# TC37XPD register map
Vendor: Infineon; Series: ATVMC; File version: 100
CPU: other r0p0, little endian, MPU, FPU, vendor SysTick, 4 interrupt priority bits
Registers are 32-bit, read-write, reset 0x0 unless marked. A register's access mark holds for its fields unless they carry their own. Offsets are from the block's base; [hi:lo] are bit positions; lines under a group give offsets from that group; {n}, {i} and the like mark numbered series.

## PSI5 (part 2 of 2)
Base 0xF0005000
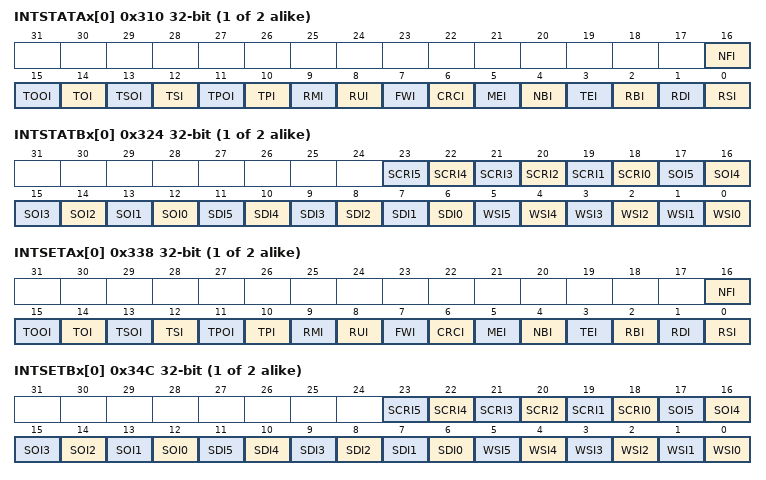
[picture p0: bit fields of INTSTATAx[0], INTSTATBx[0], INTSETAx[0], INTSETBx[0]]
{0x310+4i} INTSTATAx[{i}] (i=0..1) ro — Interrupt Status Register A 0 resetvalue={Application Reset:0x0}
  [16] NFI — No Frame Received Interrupt Flag NFI. This bit is set at the end of a slot if a frame is expected in the slot and SOF was not received in the slot. A special case is where an SOF is received in slot 0. In this scenario the NFI bit is only set at the end of slot 1 if a frame is expected in slot 1 and an EOF was not received in slot 1. If only the two start bits are received and no further data this x201c SOF x201d is discarded completely and treated like no frame received as well. If the x201c SOF only frame x201d crosses the WDL NFI occurs after WDL and EOF detection. If RCRBx.VBS is set an empty frame is stored anyhow. In this case RDIx is issued as well. The only valid information is SC TS captured at the end of the slot and this bit NFI . This bit can be cleared by bit INTCLRAx.NFI. This bit can be set by bit INTSETAx.NFI. This bit is set independently from INTENAx.
  [15] TOOI — Transmit Shift Overflow Interrupt Request Flag TOOI. This bit is set after if SORL H is written while TOF is set. The old data is NOT overwritten. This bit can be cleared by bit INTCLRAx.TOOI. This bit can be set by bit INTSETAx.TOOI. This bit is set independently from INTENAx.
  [14] TOI — Transfer Output Interrupt Request Flag TOI. This bit is set after last bit to be transferred has been moved from SORL H to the pulse generator. Thus a new value can be written to SORL Hx. This bit is NOT cleared by writing SORL Hx. This bit can be cleared by bit INTCLRAx.TOI. This bit can be set by bit INTSETAx.TOI. This bit is set independently from INTENAx.
  [13] TSOI — Transmit Shift Overflow Interrupt Request Flag TSOI. This bit is set after if SSRL H is written while TSF is set. The old data is NOT overwritten. This bit can be cleared by bit INTCLRAx.TSOI. This bit can be set by bit INTSETAx.TSOI. This bit is set independently from INTENAx.
  [12] TSI — Transfer Shift Interrupt Request Flag TSI. This bit is set after data to be transferred has been moved from SSRL H to SORL H. Thus a new value can be written to SSRL Hx. This bit is NOT cleared by writing SSRL Hx. This bit can be cleared by bit INTCLRAx.TSI. This bit can be set by bit INTSETAx.TSI. This bit is set independently from INTENAx.
  [11] TPOI — Transmit Preparation Overflow Interrupt Request Flag TPOI. This bit is set after if SDRL H is written while TPF is set. The old data is NOT overwritten. This bit can be cleared by bit INTCLRAx.TPOI. This bit can be set by bit INTSETAx.TPOI. This bit is set independently from INTENAx.
  [10] TPI — Transfer Preparation Interrupt Request Flag TPI. This bit is set after data to be transferred has been moved from SDRL H to SSRL H. Thus a new value can be written to SDRL Hx and the prepared data can be checked and modified by SW. This bit is automatically cleared by writing SDRx. This is an exception It allows for DMA transfers without CPU activity. This bit can be cleared by bit INTCLRAx.TDI. This bit can be set by bit INTSETAx.TDI. This bit is set independently from INTENAx.
  [9] RMI — Receive Memory Overflow Flag RMI. This bit is set after a frame has been received while RDIOVx.RDI RFCx.WRP is set. I.e. the kernel wants to set flag RDIxWRP and finds this flag already set. The old data is overwritten by the new data in the buffer memory. This bit can be cleared by bit INTCLRAx.RMIx. This bit can be set by bit INTSETAx.RMIx. This bit is set independently from INTENAx.
  [8] RUI — Receive Memory Underrun Interrupt Request Flag RUI. This bit is set after a SPB master reads from FIFO while no new data was available. See RFCx This bit can be cleared by bit INTCLRAx.RUI. This bit can be set by bit INTSETAx.RUI. This bit is set independently from INTENAx.
  [7] FWI — FIFO Warning Level Request Flag FWI. This bit is set after if the configured warning level of the FIFOx was reached. See RFCx This bit can be cleared by bit INTCLRAx.FWI. This bit can be set by bit INTSETAx.FWI. This bit is set independently from INTENAx.
  [6] CRCI — CRC Error Request Flag CRCI. This bit is set if the CRC fails. Set as well if CRC can not be calculated PDL 0 CRC cut off by Manchester Error too few bits BOT Sync Pulse This bit can be cleared by bit INTCLRAx.CRCI. This bit can be set by bit INTSETAx.CRCI. This bit is set independently from INTENAx.
  [5] MEI — Error in Message Bits Flag MEI. This bit is set if a manchester error occurred in Bit M0 or M1. Only if configured in RCRBx.MSG Note that the frame after the error might be completely wrong. The frame is no longer checked from the Manchester error on zeros are inserted and a start of frame is looked for no occurrence of edges for at least one bit time followed by two zero bits. This bit can be cleared by bit INTCLRAx.MEI. This bit can be set by bit INTSETAx.MEI. This bit is set independently from INTENAx.
  [4] NBI — Number of Bits Wrong Request Flag NBI. This bit is set if the last frame received less bits than expected but no Manchester coding error occurred until S1 S2 M0 and M1 where received. I. e. fewer bits or Manchester error after M1 received. Note that the frame after the error might be completely wrong. The frame is no longer checked from the Manchester error on zeros are inserted and a start of frame is looked for no occurrence of edges for at least one bit time followed by two zero bits. This bit can be cleared by bit INTCLRAx.NBI. This bit can be set by bit INTSETAx.NBI. This bit is set independently from INTENAx.
  [3] TEI — Time Slot Error Interrupt Request Flag TEI. In Synchronous Mode RCRAx.ASYN 0 this bit is set if the SOF and the EOF of a frame are received in different time slots. The slots are constraint by the watch dog timer see WDTxy . In Asynchronous Mode RCRAx.ASYN 1 this bit is set if the distance between two frames is longer than specified in WDL0. This bit can be cleared by bit INTCLRAx.TEI. This bit can be set by bit INTSETAx.TEI. This bit is set independently from INTENAx.
  [2] RBI — Receive Buffer Overflow Interrupt Request Flag RBI. This bit is set after a frame has been received while the old one was not read from RDRHx. I.e. the kernel wants to set any of the two interrupts RSI and RDI and finds any of these two interrupts already set. The old data is overwritten by the new data. Thus RBI can be ignored if the receive memory is used. This bit is NOT cleared by reading RDRx. This bit can be cleared by bit INTCLRAx.RBI. This bit can be set by bit INTSETAx.RBI. This bit is set independently from INTENAx.
  [1] RDI — Receive Data Interrupt Request Flag RDI. RDI is activated when a received frame is moved to a Receive Data Register RDRL Hx. Both RDI and RSI will be issued together at correct reception. This bit can be cleared by bit INTCLRAx.RDI. This bit can be set by bit INTSETAx.RDI. This bit is set independently from INTENAx.
  [0] RSI — Receive Success Interrupt Request Flag RSI. This bit is set at the successfully received end of a frame. It indicates that this frame is free of the errors NFI TEI NBI MEI CRCI if selected to be taken into account in register GCR. This bit can be cleared by bit INTCLRAx.RSI. This bit can be set by bit INTSETAx.RSI. This bit is set independently from INTENAx.
{0x324+4i} INTSTATBx[{i}] (i=0..1) ro — Interrupt Status Register B 0 resetvalue={Application Reset:0x0}
  [n+18] SCRI{n} (n=0..5) — Serial Data CRC Error Request Flag SCRI5. This bit is set if the CRC of the serial message fails. This includes a check of the Messaging bit field for correct 0 values of bit 1 in frames 7 13 and 18. This bit can be cleared by bit INTCLRBx.SCRIy. This bit can be set by bit INTSETx.SCRIy. This bit is set independently from INTENBx.
  [n+12] SOI{n} (n=0..5) — Serial Data Buffer Overrun Interrupt Request Flag SOI5. This bit is set if the HW wants to set SDIy while SDIy is still set. This bit can be cleared by bit INTCLRBx.SOIy. This bit can be set by bit INTSETBx.SOIy. This bit is set independently from INTENBx.
  [n+6] SDI{n} (n=0..5) — Serial Data Receive Interrupt Request Flag SDI5. This bit is set after all serial data bits have been received via the Messaging bit field of slot y. This does NOT indicates a successful check of the CRC. This bit can be cleared by bit INTCLRBx.SDIy. This bit can be set by bit INTSETBx.SDIy. This bit is set independently from INTENBx.
  [n] WSI{n} (n=0..5) — Wrong Serial Protocol Error Request Flag WSI5. This bit is set if the Messaging bits are configured and do not show a start sequence for more than 18 frames of slot y. This bit can be cleared by bit INTCLRBx.WSIy. This bit can be set by bit INTSETBx.WSIy. This bit is set independently from INTENBx.
{0x338+4i} INTSETAx[{i}] (i=0..1) wo — Interrupt Set Register A 0 resetvalue={Application Reset:0x0}
  [16] NFI — Set Interrupt Request Flag NFI NFI. Setting this bit set bit INTSTATx.NFI. Clearing this bit has no effect. Reading this bit returns always zero.
  [15] TOOI — Set Interrupt Request Flag TOOI TOOI. Setting this bit set bit INTSTATx.TOOI. Clearing this bit has no effect. Reading this bit returns always zero.
  [14] TOI — Set Interrupt Request Flag TOI TOI. Setting this bit set bit INTSTATx.TOI. Clearing this bit has no effect. Reading this bit returns always zero.
  [13] TSOI — Set Interrupt Request Flag TSOI TSOI. Setting this bit set bit INTSTATx.TSOI. Clearing this bit has no effect. Reading this bit returns always zero.
  [12] TSI — Set Interrupt Request Flag TSI TSI. Setting this bit set bit INTSTATx.TSI. Clearing this bit has no effect. Reading this bit returns always zero.
  [11] TPOI — Set Interrupt Request Flag TPOI TPOI. Setting this bit set bit INTSTATx.TPOI. Clearing this bit has no effect. Reading this bit returns always zero.
  [10] TPI — Set Interrupt Request Flag TPI TPI. Setting this bit set bit INTSTATx.TPI. Clearing this bit has no effect. Reading this bit returns always zero.
  [9] RMI — Set Interrupt Request Flag RMI RMI. Setting this bit set bit INTSTATx.RMI. Clearing this bit has no effect. Reading this bit returns always zero.
  [8] RUI — Set Interrupt Request Flag RUI RUI. Setting this bit set bit INTSTATx.RUI. Clearing this bit has no effect. Reading this bit returns always zero.
  [7] FWI — Set Interrupt Request Flag FWI FWI. Setting this bit set bit INTSTATx.FWI. Clearing this bit has no effect. Reading this bit returns always zero.
  [6] CRCI — Set Interrupt Request Flag CRCI CRCI. Setting this bit set bit INTSTATx.CRCI. Clearing this bit has no effect. Reading this bit returns always zero.
  [5] MEI — Set Interrupt Request Flag MEI MEI. Setting this bit set bit INTSTATx.MEI. Clearing this bit has no effect. Reading this bit returns always zero.
  [4] NBI — Set Interrupt Request Flag NBI NBI. Setting this bit set bit INTSTATx.NBI. Clearing this bit has no effect. Reading this bit returns always zero.
  [3] TEI — Set Interrupt Request Flag TEI TEI. Setting this bit set bit INTSTATx.TEI. Clearing this bit has no effect. Reading this bit returns always zero.
  [2] RBI — Set Interrupt Request Flag RBI RBI. Setting this bit set bit INTSTATx.RBI. Clearing this bit has no effect. Reading this bit returns always zero.
  [1] RDI — Set Interrupt Request Flag RDI RDI. Setting this bit set bit INTSTATx.RDI. Clearing this bit has no effect. Reading this bit returns always zero.
  [0] RSI — Set Interrupt Request Flag RSI RSI. Setting this bit set bit INTSTATx.RSI. Clearing this bit has no effect. Reading this bit returns always zero.
{0x34C+4i} INTSETBx[{i}] (i=0..1) wo — Interrupt Set Register B 0 resetvalue={Application Reset:0x0}
  [n+18] SCRI{n} (n=0..5) — Set Interrupt Request Flag SCRI5 SCRI5. Setting this bit set bit INTSTATx.SCRIy. Clearing this bit has no effect. Reading this bit returns always zero.
  [n+12] SOI{n} (n=0..5) — Set Interrupt Request Flag SOI5 SOI5. Setting this bit set bit INTSTATx.SOIy. Clearing this bit has no effect. Reading this bit returns always zero.
  [n+6] SDI{n} (n=0..5) — Set Interrupt Request Flag SDI5 SDI5. Setting this bit set bit INTSTATx.SDIy. Clearing this bit has no effect. Reading this bit returns always zero.
  [n] WSI{n} (n=0..5) — Set Interrupt Request Flag WSI5 WSI5. Setting this bit set bit INTSTATx.WSIy. Clearing this bit has no effect. Reading this bit returns always zero.
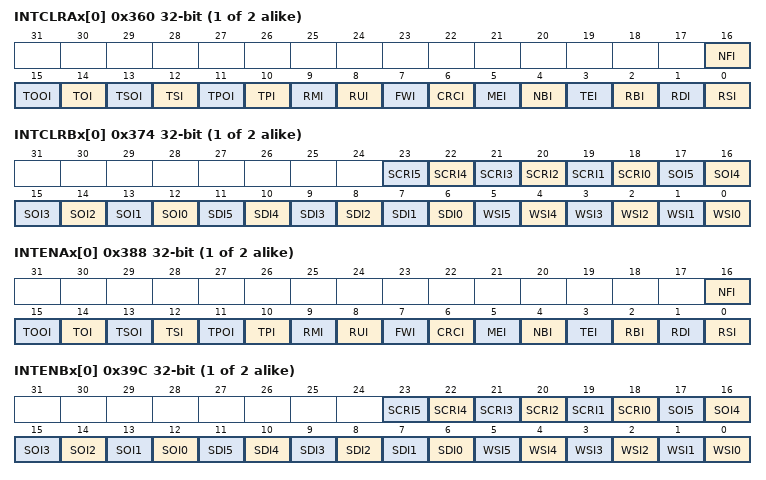
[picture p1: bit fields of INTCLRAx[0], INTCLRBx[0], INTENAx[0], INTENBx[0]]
{0x360+4i} INTCLRAx[{i}] (i=0..1) wo — Interrupt Clear Register A 0 resetvalue={Application Reset:0x0}
  [16] NFI — Clear Interrupt Request Flag NFI NFI. Setting this bit clears bit INTSTATx.NFI. Clearing this bit has no effect. Reading this bit returns always zero.
  [15] TOOI — Clear Interrupt Request Flag TOOI TOOI. Setting this bit clears bit INTSTATx.TOOI. Clearing this bit has no effect. Reading this bit returns always zero.
  [14] TOI — Clear Interrupt Request Flag TOI TOI. Setting this bit clears bit INTSTATx.TOI. Clearing this bit has no effect. Reading this bit returns always zero.
  [13] TSOI — Clear Interrupt Request Flag TSOI TSOI. Setting this bit clears bit INTSTATx.TSOI. Clearing this bit has no effect. Reading this bit returns always zero.
  [12] TSI — Clear Interrupt Request Flag TSI TSI. Setting this bit clears bit INTSTATx.TSI. Clearing this bit has no effect. Reading this bit returns always zero.
  [11] TPOI — Clear Interrupt Request Flag TPOI TPOI. Setting this bit clears bit INTSTATx.TPOI. Clearing this bit has no effect. Reading this bit returns always zero.
  [10] TPI — Clear Interrupt Request Flag TPI TPI. Setting this bit clears bit INTSTATx.TPI. Clearing this bit has no effect. Reading this bit returns always zero.
  [9] RMI — Clear Interrupt Request Flag RMI RMI. Setting this bit clears bit INTSTATx.RMI. Clearing this bit has no effect. Reading this bit returns always zero.
  [8] RUI — Clear Interrupt Request Flag RUI RUI. Setting this bit clears bit INTSTATx.RUI. Clearing this bit has no effect. Reading this bit returns always zero.
  [7] FWI — Clear Interrupt Request Flag FWI FWI. Setting this bit clears bit INTSTATx.FWI. Clearing this bit has no effect. Reading this bit returns always zero.
  [6] CRCI — Clear Interrupt Request Flag CRCI CRCI. Setting this bit clears bit INTSTATx.CRCI. Clearing this bit has no effect. Reading this bit returns always zero.
  [5] MEI — Clear Interrupt Request Flag MEI MEI. Setting this bit clears bit INTSTATx.MEI. Clearing this bit has no effect. Reading this bit returns always zero.
  [4] NBI — Clear Interrupt Request Flag NBI NBI. Setting this bit clears bit INTSTATx.NBI. Clearing this bit has no effect. Reading this bit returns always zero.
  [3] TEI — Clear Interrupt Request Flag TEI TEI. Setting this bit clears bit INTSTATx.TEI. Clearing this bit has no effect. Reading this bit returns always zero.
  [2] RBI — Clear Interrupt Request Flag RBI RBI. Setting this bit clears bit INTSTATx.RBI. Clearing this bit has no effect. Reading this bit returns always zero.
  [1] RDI — Clear Interrupt Request Flag RDI RDI. Setting this bit clears bit INTSTATx.RDI. Clearing this bit has no effect. Reading this bit returns always zero.
  [0] RSI — Clear Interrupt Request Flag RSI RSI. Setting this bit clears bit INTSTATx.RSI. Clearing this bit has no effect. Reading this bit returns always zero.
{0x374+4i} INTCLRBx[{i}] (i=0..1) wo — Interrupt Clear Register A 0 resetvalue={Application Reset:0x0}
  [n+18] SCRI{n} (n=0..5) — Clear Interrupt Request Flag SCRI5 SCRI5. Setting this bit clears bit INTSTATx.SCRIy. Clearing this bit has no effect. Reading this bit returns always zero.
  [n+12] SOI{n} (n=0..5) — Clear Interrupt Request Flag SOI5 SOI5. Setting this bit clears bit INTSTATx.SOIy. Clearing this bit has no effect. Reading this bit returns always zero.
  [n+6] SDI{n} (n=0..5) — Clear Interrupt Request Flag SDI5 SDI5. Setting this bit clears bit INTSTATx.SDIy. Clearing this bit has no effect. Reading this bit returns always zero.
  [n] WSI{n} (n=0..5) — Clear Interrupt Request Flag WSI5 WSI5. Setting this bit clears bit INTSTATx.WSIy. Clearing this bit has no effect. Reading this bit returns always zero.
{0x388+4i} INTENAx[{i}] (i=0..1) — Interrupt Enable Register A 0 resetvalue={Application Reset:0x0}
  [16] NFI — Enable Interrupt Request NFI NFI
  [15] TOOI — Enable Interrupt Request TOOI TOOI
  [14] TOI — Enable Interrupt Request TOI TOI
  [13] TSOI — Enable Interrupt Request TSOI TSOI
  [12] TSI — Enable Interrupt Request TSI TSI
  [11] TPOI — Enable Interrupt Request TPOI TPOI
  [10] TPI — Enable Interrupt Request TPI TPI
  [9] RMI — Enable Interrupt Request RMII RMI
  [8] RUI — Enable Interrupt Request RUI RUI
  [7] FWI — Enable Interrupt Request FWI FWI
  [6] CRCI — Enable Interrupt Request CRCI CRCI
  [5] MEI — Enable Interrupt Request MEII MEI
  [4] NBI — Enable Interrupt Request NBI NBI
  [3] TEI — Enable Interrupt Request TEI TEI
  [2] RBI — Enable Interrupt Request RBI RBI
  [1] RDI — Enable Interrupt Request RDI RDI
  [0] RSI — Enable Interrupt Request RSI RSI
{0x39C+4i} INTENBx[{i}] (i=0..1) — Interrupt Enable Register B 0 resetvalue={Application Reset:0x0}
  [n+18] SCRI{n} (n=0..5) — Enable Interrupt Request SCRI5 SCRI5
  [n+12] SOI{n} (n=0..5) — Enable Interrupt Request SOI5 SOI5
  [n+6] SDI{n} (n=0..5) — Enable Interrupt Request SDI5 SDI5
  [n] WSI{n} (n=0..5) — Enable Interrupt Request WSI5 WSI5
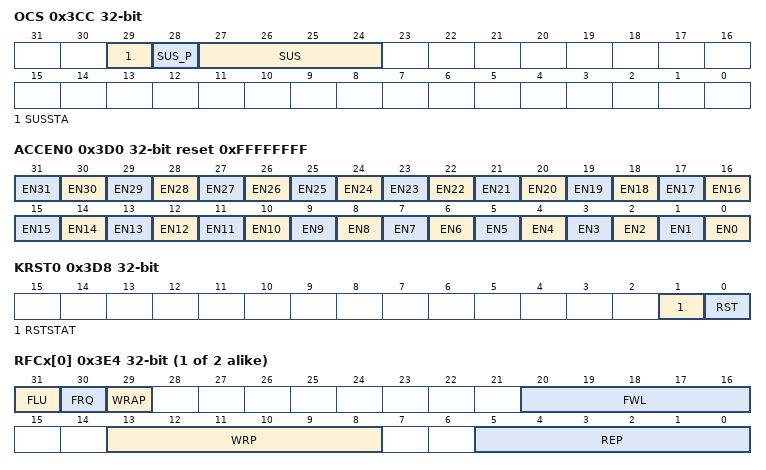
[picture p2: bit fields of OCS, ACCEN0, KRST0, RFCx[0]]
0x3CC OCS access per field — OCDS Control and Status resetvalue={Debug Reset:0x0}
  [29] SUSSTA ro — Suspend State SUSSTA
  [28] SUS_P wo — SUS Write Protection SUS P. SUS is only written when SUS P is 1 otherwise unchanged. Read as 0.
  [27:24] SUS rw — OCDS Suspend Control SUS. Controls the sensitivity to the suspend signal coming from the OCDS Trigger Switch OTGS
0x3D0 ACCEN0 reset 0xFFFFFFFF — Access Enable Register 0 resetvalue={Application Reset:0x0FFFFFFFF}
  [n] EN{n} (n=0..31) — Access Enable for Master TAG ID 31 EN31. This bit enables write access to the module kernel addresses for transactions with the Master TAG ID n
0x3D8 KRST0 access per field — Kernel Reset Register 0 resetvalue={Application Reset:0x0}
  [1] RSTSTAT ro — Kernel Reset Status RSTSTAT. This bit indicates wether a kernel reset was executed or not. This bit is set by the BPI FPI after the execution of a kernel reset in the same clock cycle both reset bits. This bit can be cleared by writing with 1 to the CLR bit in the related KRSTCLR register.
  [0] RST rw — Kernel Reset RST. This reset bit can be used to request for a kernel reset. The kernel reset will be executed if the reset bits of both kernel registers are set. The RST bit will be cleared re set to 0 by the BPI FPI after the kernel reset was executed.
0x3DC KRST1 — Kernel Reset Register 1 resetvalue={Application Reset:0x0}
  [0] RST — Kernel Reset RST. This reset bit can be used to request for a kernel reset. The kernel reset will be executed if the reset bits of both kernel reset registers is set. The RST bit will be cleared re set to 0 by the BPI FPI after the kernel reset was executed.
0x3E0 KRSTCLR wo — Kernel Reset Status Clear Register resetvalue={Application Reset:0x0}
  [0] CLR — Kernel Reset Status Clear CLR. Read always as 0.
{0x3E4+4i} RFCx[{i}] (i=0..1) access per field — Receive FIFO Control Register 0 resetvalue={Application Reset:0x0}
  [31] FLU wo — Flush FLU. if set FIFO read and write pointers are cleared. Bits and WRAP are cleared. SW needs to clear interrupts as needed. This bit can only be set and is cleared by HW. Always read as 0.
  [30] FRQ ro — Flush Request FRQ. if set FIFO read and write pointers are not incremented any more due to excessive RMI. Too many overrun conditions . This bit is cleared when FLU is set.
  [29] WRAP ro — Write Pointer WRAP Indicator WRAP. If set the Write Pointer is one wrap around ahead of the Read Pointer. It is cleared if the Read Pointer wraps around too or when FLU is set by SW.
  [20:16] FWL rw — FIFO Warning Level FWL. Number of new entries at which the FIFO Warning Interrupt FWIx is set automatically. For calculation WRP and REP are used. I.e. only if the memory is read via RDFx this works properly.
  [13:8] WRP ro — FIFO Ring Buffer Write Pointer WRP. points to the buffer written last. Incremented before write. The last bit indicates if RDMxH or RDMxL is written. This LSB is ignored for FWL comparison WRP REP collision RBI RUI .
  [5:0] REP ro — FIFO Read Pointer REP. points to the buffer to be read next. Incremented after read. The last bit bit indicates if RDMxH or RDMxL is read. This LSB is ignored for FWL comparison WRP REP collision RBI RUI
{0x3F8+4i} RDFx[{i}] (i=0..1) ro — Receive Data FIFO 0 resetvalue={Application Reset:0x0}
  [31:0] RD — RD RD. Shows the content of RDML Hxy y RFCx.REP 5 1 L H RFCx.REP 0 . Reading this register triggers incrementation of REP and presentation of next FIFO value at next read access Once a complete buffer is read 64 bit 2 accesses to RDF all overview flags for this very buffer are cleared automatically.
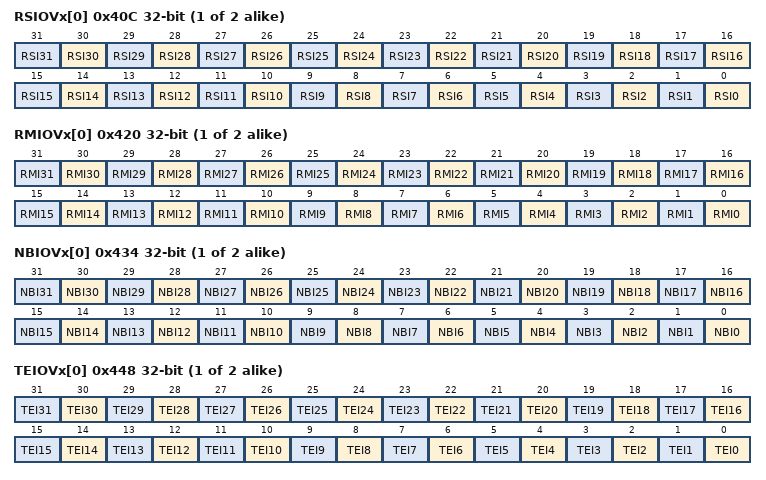
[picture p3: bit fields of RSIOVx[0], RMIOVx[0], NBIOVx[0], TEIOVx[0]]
{0x40C+4i} RSIOVx[{i}] (i=0..1) ro — RSI Overview Register 0 resetvalue={Application Reset:0x0}
  [n] RSI{n} (n=0..31) — RSI Flag of Buffer 31 RSI31. Copied from INTSTATAx at frame end while RFCx.WRP pointed to buffer y. This bit can be cleared by bit RSICLRx.RSIy. This bit can be set by bit RSISETx.RSIy.
{0x420+4i} RMIOVx[{i}] (i=0..1) ro — RMI Overview Register 0 resetvalue={Application Reset:0x0}
  [n] RMI{n} (n=0..31) — RMI Flag of Buffer 31 RMI31. Copied from INTSTATAx at frame end while RFCx.WRP pointed to buffer y. This bit can be cleared by bit RMICLRx.RMIy. This bit can be set by bit RMISETx.RMIy.
{0x434+4i} NBIOVx[{i}] (i=0..1) ro — NBI Overview Register 0 resetvalue={Application Reset:0x0}
  [n] NBI{n} (n=0..31) — NBI Flag of Buffer 31 NBI31. Copied from INTSTATAx at frame end while RFCx.WRP pointed to buffer y. This bit can be cleared by bit NBICLRx.NBIy. This bit can be set by bit NBISETx.NBIy.
{0x448+4i} TEIOVx[{i}] (i=0..1) ro — TEI Overview Register 0 resetvalue={Application Reset:0x0}
  [n] TEI{n} (n=0..31) — TEI Flag of Buffer 31 TEI31. Copied from INTSTATAx at frame end while RFCx.WRP pointed to buffer y. This bit can be cleared by bit TEICLRx.TEIy. This bit can be set by bit TEISETx.TEIy.
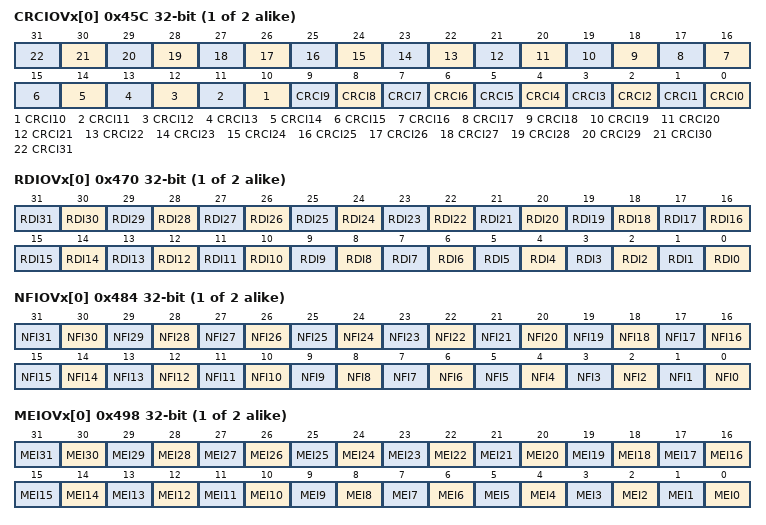
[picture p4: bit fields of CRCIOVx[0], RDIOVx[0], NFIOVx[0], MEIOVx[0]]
{0x45C+4i} CRCIOVx[{i}] (i=0..1) ro — CRCI Overview Register 0 resetvalue={Application Reset:0x0}
  [n] CRCI{n} (n=0..31) — CRCI Flag of Buffer 31 CRCI31. Copied from INTSTATAx at frame end while RFCx.WRP pointed to buffer y. This bit can be cleared by bit CRCICLRx.CRCIy. This bit can be set by bit CRCISETx.CRCIy.
{0x470+4i} RDIOVx[{i}] (i=0..1) ro — RDI Overview Register 0 resetvalue={Application Reset:0x0}
  [n] RDI{n} (n=0..31) — RDI Flag of Buffer 31 RDI31. Copied from INTSTATAx at frame end while RFCx.WRP pointed to buffer y. This bit can be cleared by bit RDICLRx.RDIy. This bit can be set by bit RDISETx.RDIy.
{0x484+4i} NFIOVx[{i}] (i=0..1) ro — NFI Overview Register 0 resetvalue={Application Reset:0x0}
  [n] NFI{n} (n=0..31) — NFI Flag of Buffer 31 NFI31. Copied from INTSTATAx at frame end while RFCx.WRP pointed to buffer y. This bit can be cleared by bit NFICLRx.NFIy. This bit can be set by bit NFISETx.NFIy.
{0x498+4i} MEIOVx[{i}] (i=0..1) ro — MEI Overview Register 0 resetvalue={Application Reset:0x0}
  [n] MEI{n} (n=0..31) — MEI Flag of Buffer 31 MEI31. Copied from INTSTATAx at frame end while RFCx.WRP pointed to buffer y. This bit can be cleared by bit MEICLRx.MEIy. This bit can be set by bit MEISETx.MEIy.
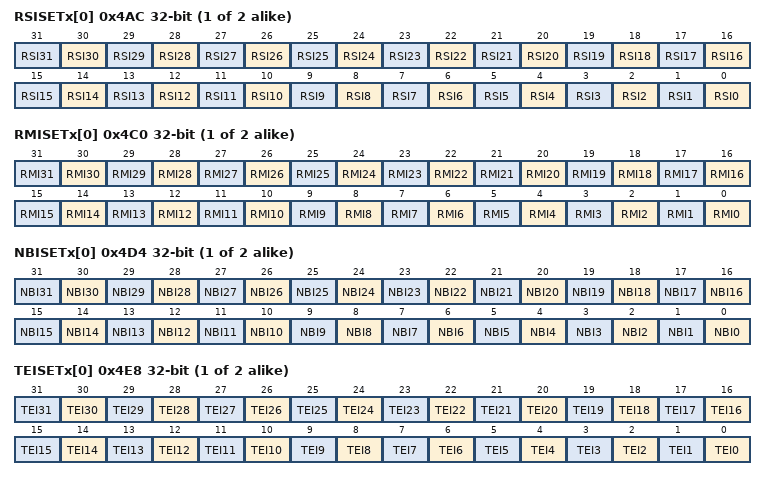
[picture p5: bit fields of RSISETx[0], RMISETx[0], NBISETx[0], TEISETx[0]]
{0x4AC+4i} RSISETx[{i}] (i=0..1) wo — RSI Overview Set Register 0 resetvalue={Application Reset:0x0}
  [n] RSI{n} (n=0..31) — Set RSI Flag of Buffer 31 RSI31. Setting this bit sets bit RSIOVx.RSIy Clearing this bit has no effect. Reading this bit returns always zero.
{0x4C0+4i} RMISETx[{i}] (i=0..1) wo — RMI Overview Set Register 0 resetvalue={Application Reset:0x0}
  [n] RMI{n} (n=0..31) — Set RMI Flag of Buffer 31 RMI31. Setting this bit sets bit RMIOVx.RMIy Clearing this bit has no effect. Reading this bit returns always zero.
{0x4D4+4i} NBISETx[{i}] (i=0..1) wo — NBI Overview Set Register 0 resetvalue={Application Reset:0x0}
  [n] NBI{n} (n=0..31) — Set NBI Flag of Buffer 31 NBI31. Setting this bit sets bit NBIOVx.NBIy Clearing this bit has no effect. Reading this bit returns always zero.
{0x4E8+4i} TEISETx[{i}] (i=0..1) wo — TEI Overview Set Register 0 resetvalue={Application Reset:0x0}
  [n] TEI{n} (n=0..31) — Set TEI Flag of Buffer 31 TEI31. Setting this bit sets bit TEIOVx.TEIy Clearing this bit has no effect. Reading this bit returns always zero.
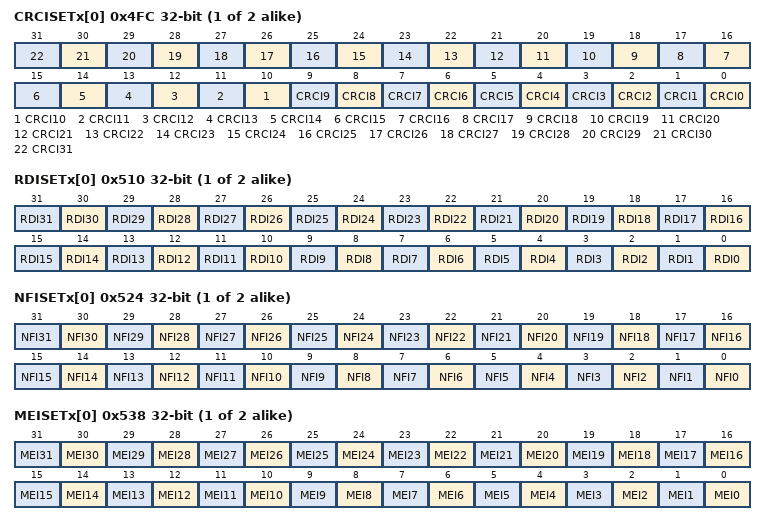
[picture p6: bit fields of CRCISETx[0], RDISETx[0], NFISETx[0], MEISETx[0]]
{0x4FC+4i} CRCISETx[{i}] (i=0..1) wo — CRCI Overview Set Register 0 resetvalue={Application Reset:0x0}
  [n] CRCI{n} (n=0..31) — Set CRCI Flag of Buffer 31 CRCI31. Setting this bit sets bit CRCIOVx.CRCIy Clearing this bit has no effect. Reading this bit returns always zero.
{0x510+4i} RDISETx[{i}] (i=0..1) wo — RDI Overview Set Register 0 resetvalue={Application Reset:0x0}
  [n] RDI{n} (n=0..31) — Set RDI Flag of Buffer 31 RDI31. Setting this bit sets bit RDIOVx.RDIy Clearing this bit has no effect. Reading this bit returns always zero.
{0x524+4i} NFISETx[{i}] (i=0..1) wo — NFI Overview Set Register 0 resetvalue={Application Reset:0x0}
  [n] NFI{n} (n=0..31) — Set NFI Flag of Buffer 31 NFI31. Setting this bit sets bit NFIOVx.NFIy Clearing this bit has no effect. Reading this bit returns always zero.
{0x538+4i} MEISETx[{i}] (i=0..1) wo — MEI Overview Set Register 0 resetvalue={Application Reset:0x0}
  [n] MEI{n} (n=0..31) — Set MEI Flag of Buffer 31 MEI31. Setting this bit sets bit MEIOVx.MEIy Clearing this bit has no effect. Reading this bit returns always zero.
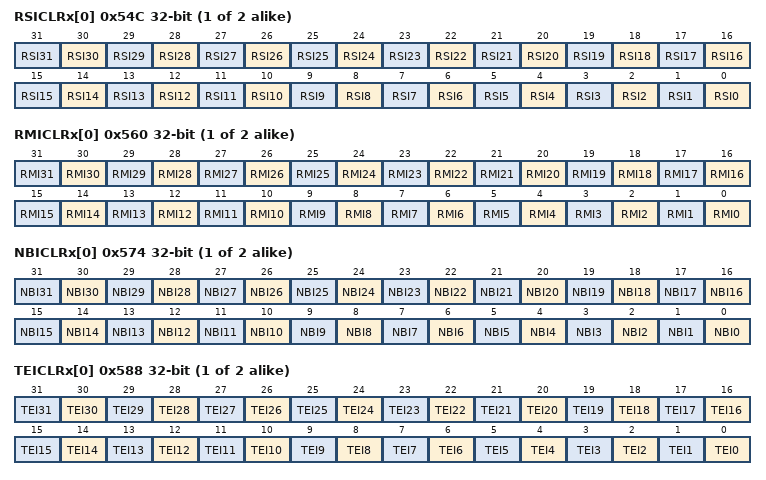
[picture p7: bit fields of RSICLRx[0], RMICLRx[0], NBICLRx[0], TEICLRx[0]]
{0x54C+4i} RSICLRx[{i}] (i=0..1) wo — RSI Overview Clear Register 0 resetvalue={Application Reset:0x0}
  [n] RSI{n} (n=0..31) — Clear RSI Flag of Buffer 31 RSI31. Setting this bit clears bit RSIOVx.RSIy Clearing this bit has no effect. Reading this bit returns always zero.
{0x560+4i} RMICLRx[{i}] (i=0..1) wo — RMI Overview Clear Register 0 resetvalue={Application Reset:0x0}
  [n] RMI{n} (n=0..31) — Clear RMI Flag of Buffer 31 RMI31. Setting this bit clears bit RMIOVx.RMIy Clearing this bit has no effect. Reading this bit returns always zero.
{0x574+4i} NBICLRx[{i}] (i=0..1) wo — NBI Overview Clear Register 0 resetvalue={Application Reset:0x0}
  [n] NBI{n} (n=0..31) — Clear NBI Flag of Buffer 31 NBI31. Setting this bit clears bit NBIOVx.NBIy Clearing this bit has no effect. Reading this bit returns always zero.
{0x588+4i} TEICLRx[{i}] (i=0..1) wo — TEI Overview Clear Register 0 resetvalue={Application Reset:0x0}
  [n] TEI{n} (n=0..31) — Clear TEI Flag of Buffer 31 TEI31. Setting this bit clears bit TEIOVx.TEIy Clearing this bit has no effect. Reading this bit returns always zero.
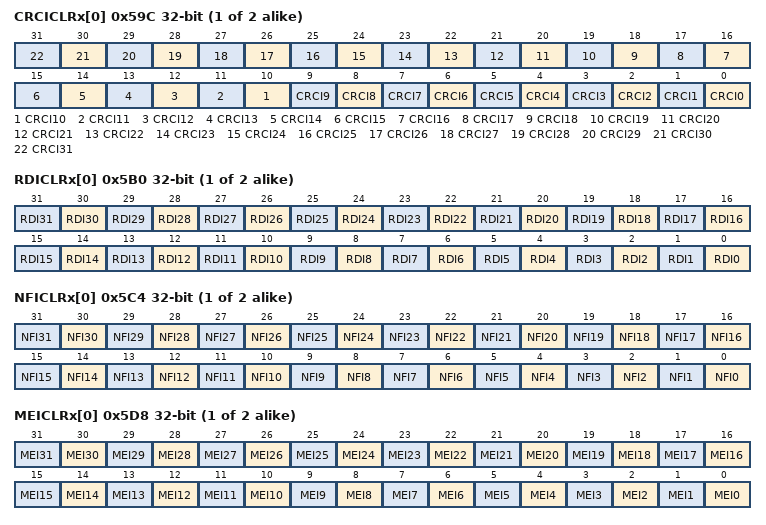
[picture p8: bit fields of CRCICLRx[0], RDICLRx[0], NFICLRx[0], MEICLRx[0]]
{0x59C+4i} CRCICLRx[{i}] (i=0..1) wo — CRCI Overview Clear Register 0 resetvalue={Application Reset:0x0}
  [n] CRCI{n} (n=0..31) — Clear CRCI Flag of Buffer 31 CRCI31. Setting this bit clears bit CRCIOVx.CRCIy Clearing this bit has no effect. Reading this bit returns always zero.
{0x5B0+4i} RDICLRx[{i}] (i=0..1) wo — RDI Overview Clear Register 0 resetvalue={Application Reset:0x0}
  [n] RDI{n} (n=0..31) — Clear RDI Flag of Buffer 31 RDI31. Setting this bit clears bit RDIOVx.RDIy Clearing this bit has no effect. Reading this bit returns always zero.
{0x5C4+4i} NFICLRx[{i}] (i=0..1) wo — NFI Overview Clear Register 0 resetvalue={Application Reset:0x0}
  [n] NFI{n} (n=0..31) — Clear NFI Flag of Buffer 31 NFI31. Setting this bit clears bit NFIOVx.NFIy Clearing this bit has no effect. Reading this bit returns always zero.
{0x5D8+4i} MEICLRx[{i}] (i=0..1) wo — MEI Overview Clear Register 0 resetvalue={Application Reset:0x0}
  [n] MEI{n} (n=0..31) — Clear MEI Flag of Buffer 31 MEI31. Setting this bit clears bit MEIOVx.MEIy Clearing this bit has no effect. Reading this bit returns always zero.
{0x600+8i} RDM[{i}] (i=0..3) group
  {0x0+8j} RDMx[{j}] (j=0..31) group
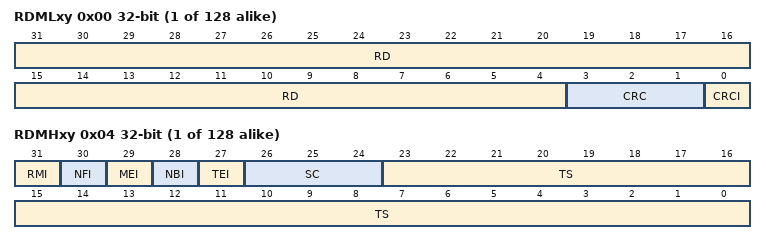
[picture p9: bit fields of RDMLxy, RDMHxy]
    0x00 RDMLxy ro — Receive Data Memory Low 00 resetvalue={Application Reset:0x0}
      [31:4] RD — RD RD. Copied from RDRLx at frame end.
      [3:1] CRC — CRC CRC. Copied from RDRLx at frame end.
      [0] CRCI — CRC Error Flag CRCI. Copied from RDRLx at frame end.
    0x04 RDMHxy ro — Receive Data Memory High 00 resetvalue={Application Reset:0x0}
      [31] RMI — Receive Memory Overflow Flag RMI. Copied from INTSTATAx at frame end.
      [30] NFI — No Frame Received Flag NFI. Copied from RDRHx at frame end.
      [29] MEI — Error in Messaging Bits Flag MEI. Copied from RDRHx at frame end.
      [28] NBI — Number of bits Error Flag NBI. Copied from RDRHx at frame end.
      [27] TEI — Time Slot Error Flag TEI. Copied from RDRHx at frame end.
      [26:24] SC — Slot Counter SC. Copied from RDRHx at frame end.
      [23:0] TS — Time Stamp TS. Copied from RDRHx at frame end.
